AUTOSAR XML (schema 4-0-3)
package /ComponentTypes
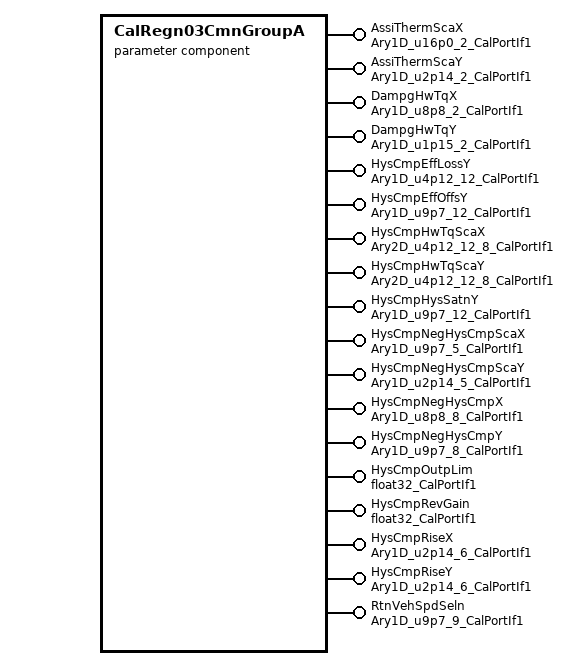
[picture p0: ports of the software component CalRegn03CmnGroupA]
  parameter sw component type CalRegn03CmnGroupA
    18 x provide port:
      AssiThermScaX: parameter-provide-com-spec{init-value=[75, 100], parameter=Ary1D}, provided-interface=Ary1D_u16p0_2_CalPortIf1
      AssiThermScaY: parameter-provide-com-spec{init-value=[16384, 13107], parameter=Ary1D}, provided-interface=Ary1D_u2p14_2_CalPortIf1
      DampgHwTqX: parameter-provide-com-spec{init-value=[2048, 2560], parameter=Ary1D}, provided-interface=Ary1D_u8p8_2_CalPortIf1
      DampgHwTqY: parameter-provide-com-spec{init-value=[32768, 0], parameter=Ary1D}, provided-interface=Ary1D_u1p15_2_CalPortIf1
      HysCmpEffLossY: parameter-provide-com-spec{init-value=12 x 0, parameter=Ary1D}, provided-interface=Ary1D_u4p12_12_CalPortIf1
      HysCmpEffOffsY: parameter-provide-com-spec{init-value=12 x 0, parameter=Ary1D}, provided-interface=Ary1D_u9p7_12_CalPortIf1
      HysCmpHwTqScaX: parameter-provide-com-spec{init-value=12 x [0, 815, 1634, 2458, 4096, 5730, 8192, 40960], parameter=Ary2D}, provided-interface=Ary2D_u4p12_12_8_CalPortIf1
      HysCmpHwTqScaY: parameter-provide-com-spec{init-value=12 x 8 x 4096, parameter=Ary2D}, provided-interface=Ary2D_u4p12_12_8_CalPortIf1
      HysCmpHysSatnY: parameter-provide-com-spec{init-value=12 x 1280, parameter=Ary1D}, provided-interface=Ary1D_u9p7_12_CalPortIf1
      HysCmpNegHysCmpScaX: parameter-provide-com-spec{init-value=[0, 128, 256, 384, 512], parameter=Ary1D}, provided-interface=Ary1D_u9p7_5_CalPortIf1
      HysCmpNegHysCmpScaY: parameter-provide-com-spec{init-value=5 x 16384, parameter=Ary1D}, provided-interface=Ary1D_u2p14_5_CalPortIf1
      HysCmpNegHysCmpX: parameter-provide-com-spec{init-value=[0, 26, 51, 102, 154, 205, 230, 256], parameter=Ary1D}, provided-interface=Ary1D_u8p8_8_CalPortIf1
      HysCmpNegHysCmpY: parameter-provide-com-spec{init-value=8 x 0, parameter=Ary1D}, provided-interface=Ary1D_u9p7_8_CalPortIf1
      HysCmpOutpLim: parameter-provide-com-spec{init-value=16, parameter=Val}, provided-interface=float32_CalPortIf1
      HysCmpRevGain: parameter-provide-com-spec{init-value=6, parameter=Val}, provided-interface=float32_CalPortIf1
      HysCmpRiseX: parameter-provide-com-spec{init-value=[0, 1556, 2097, 2540, 2982, 3277], parameter=Ary1D}, provided-interface=Ary1D_u2p14_6_CalPortIf1
      HysCmpRiseY: parameter-provide-com-spec{init-value=[0, 9863, 12878, 14811, 15974, 16384], parameter=Ary1D}, provided-interface=Ary1D_u2p14_6_CalPortIf1
      RtnVehSpdSeln: parameter-provide-com-spec{init-value=[0, 384, 896, 1536, 2560, 3840, 5760, 7680, 10240], parameter=Ary1D}, provided-interface=Ary1D_u9p7_9_CalPortIf1
